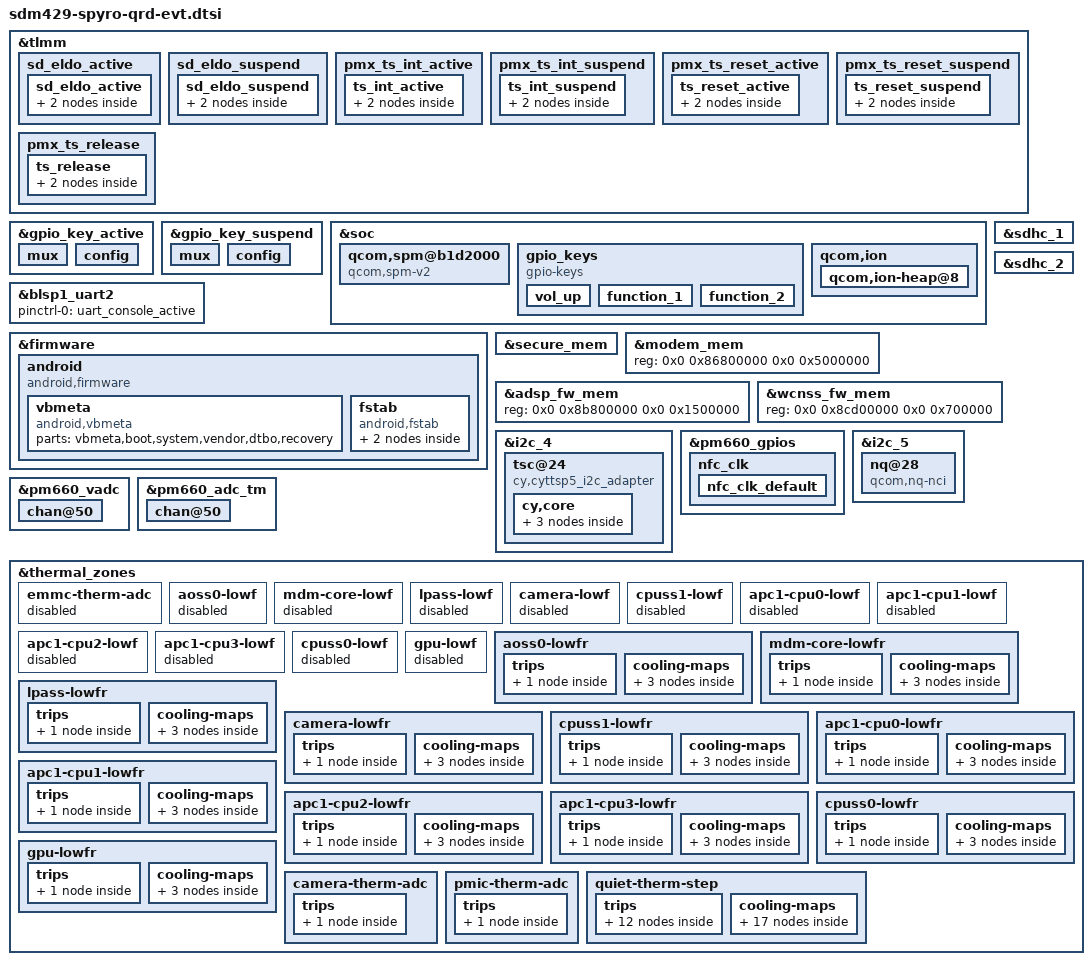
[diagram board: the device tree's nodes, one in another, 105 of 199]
/*
 * Copyright (c) 2019, The Linux Foundation. All rights reserved.
 *
 * This program is free software; you can redistribute it and/or modify
 * it under the terms of the GNU General Public License version 2 and
 * only version 2 as published by the Free Software Foundation.
 *
 * This program is distributed in the hope that it will be useful,
 * but WITHOUT ANY WARRANTY; without even the implied warranty of
 * MERCHANTABILITY or FITNESS FOR A PARTICULAR PURPOSE.  See the
 * GNU General Public License for more details.
 */

#include "sdm429-spyro-qrd-mdss-panels.dtsi"
#include "sdm429-spyro-qrd-evt-camera.dtsi"
#include "sdm429-spyro-qrd-evt-audio.dtsi"
#include <dt-bindings/thermal/thermal.h>

&tlmm {
	sd_eldo_active {
		sd_eldo_active: sd_eldo_active {
			mux {
				pins = "gpio91";
				function = "gpio";
			};

			config {
				pins = "gpio91";
				drive-strength = <2>;
				bias-pull-up;
			};
		};
	};

	sd_eldo_suspend {
		sd_eldo_suspend: sd_eldo_suspend {
			mux {
				pins = "gpio91";
				function = "gpio";
			};

			config {
				pins = "gpio91";
				drive-strength = <2>;
				bias-disable;
			};
		};
	};
};

&gpio_key_active {
	mux {
		pins = "gpio127", "gpio128", "gpio35", "gpio126";
		function = "gpio";
	};

	config {
		pins = "gpio127", "gpio128", "gpio35", "gpio126";
		drive-strength = <2>;
		bias-pull-up;
	};
};

&gpio_key_suspend {
	mux {
		pins = "gpio127", "gpio128", "gpio35", "gpio126";
		function = "gpio";
	};

	config {
		pins = "gpio127", "gpio128", "gpio35", "gpio126";
		drive-strength = <2>;
		bias-pull-up;
	};
};

&soc {
	/delete-node/ qcom,spm@b1d2000;
	qcom,spm@b1d2000 {
		compatible = "qcom,spm-v2";
		#address-cells = <1>;
		#size-cells = <1>;
		reg = <0xb1d2000 0x1000>;
		qcom,name = "system-cci";
		qcom,saw2-ver-reg = <0xfd0>;
		qcom,saw2-cfg = <0x14>;
		qcom,saw2-spm-dly= <0x3C102800>;
		qcom,saw2-spm-ctl = <0xe>;
		qcom,cpu-vctl-list = <&CPU0 &CPU1 &CPU2 &CPU3>;
		qcom,vctl-timeout-us = <500>;
		qcom,vctl-port = <0x0>;
		qcom,vctl-port-ub = <0x1>;
		qcom,pfm-port = <0x2>;
	};

	gpio_keys: gpio_keys {
		compatible = "gpio-keys";
		label = "gpio-keys";
		pinctrl-names = "default";
		pinctrl-0 = <&gpio_key_active>;
		pinctrl-1 = <&gpio_key_suspend>;

		vol_up: vol_up {
			label = "volume_up";
			gpios = <&tlmm 35 0x1>;
			linux,input-type = <1>;
			linux,code = <115>;
			debounce-interval = <15>;
			linux,can-disable;
			gpio-key,wakeup;
		};

		function_1: function_1 {
			label = "function_1";
			gpios = <&tlmm 127 0x1>;
			linux,input-type = <1>;
			linux,code = <116>;
			debounce-interval = <15>;
			linux,can-disable;
			gpio-key,wakeup;
		};

		function_2: function_2 {
			label = "function_2";
			gpios = <&tlmm 126 0x1>;
			linux,input-type = <1>;
			linux,code = <117>;
			debounce-interval = <15>;
			linux,can-disable;
			gpio-key,wakeup;
		};
	};
};

&blsp1_uart2 {
	status = "ok";
	pinctrl-names = "default";
	pinctrl-0 = <&uart_console_active>;
};

&sdhc_1 {
	/* device core power supply */
	vdd-supply = <&L19A>;
	qcom,vdd-voltage-level = <2900000 3200000>;
	qcom,vdd-current-level = <200 570000>;

	/* device communication power supply */
	vdd-io-supply = <&L13A>;
	qcom,vdd-io-always-on;
	qcom,vdd-io-lpm-sup;
	qcom,vdd-io-voltage-level = <1800000 1800000>;
	qcom,vdd-io-current-level = <0 60000>;

	pinctrl-names = "active", "sleep";
	pinctrl-0 = <&sdc1_clk_on &sdc1_cmd_on &sdc1_data_on &sdc1_rclk_on>;
	pinctrl-1 = <&sdc1_clk_off &sdc1_cmd_off &sdc1_data_off &sdc1_rclk_off>;

	qcom,clk-rates = <400000 20000000 25000000 50000000 100000000 192000000
								384000000>;
	qcom,nonremovable;
	qcom,bus-speed-mode = "HS400_1p8v", "HS200_1p8v", "DDR_1p8v";

	status = "ok";
};

&sdhc_2 {
	/* device core power supply for sd card*/
	vdd-supply = <&vreg_sd_vdd>;
	qcom,vdd-voltage-level = <2950000 2950000>;
	qcom,vdd-current-level = <15000 800000>;

	/* device communication power supply for msm_io*/
	vdd-io-supply = <&vreg_sd_pad>;
	qcom,vdd-io-voltage-level = <1800000 2950000>;
	qcom,vdd-io-current-level = <200 22000>;

	pinctrl-names = "active", "sleep";
	pinctrl-0 = <&sdc2_clk_on &sdc2_cmd_on &sdc2_data_on &sdc2_cd_on
							&sd_eldo_active>;
	pinctrl-1 = <&sdc2_clk_off &sdc2_cmd_off &sdc2_data_off &sdc2_cd_off
							&sd_eldo_suspend>;

	cd-gpios = <&tlmm 67 0x0>;

	qcom,clk-rates = <400000 20000000 25000000 50000000 100000000
								200000000>;

	qcom,bus-speed-mode = "SDR12", "SDR25", "SDR50", "DDR50", "SDR104";

	status = "ok";
};

&firmware {
	android {
		compatible = "android,firmware";
		vbmeta {
			compatible = "android,vbmeta";
			parts = "vbmeta,boot,system,vendor,dtbo,recovery";
		};
		fstab {
			compatible = "android,fstab";
			vendor {
				compatible = "android,vendor";
				dev =
		"/dev/block/platform/soc/7824900.sdhci/by-name/vendor";
				type = "ext4";
				mnt_flags = "ro,barrier=1,discard";
				fsmgr_flags = "wait";
				status = "ok";
			};
			system {
				compatible = "android,system";
				dev =
		"/dev/block/platform/soc/7824900.sdhci/by-name/system";
				type = "ext4";
				mnt_flags = "ro,barrier=1,discard";
				fsmgr_flags = "wait";
				status = "ok";
			};
		};
	};
};

&soc {
	qcom,ion {
		qcom,ion-heap@8 { /* CP_MM HEAP */
			reg = <8>;
			memory-region = <&secure_mem>;
			qcom,ion-heap-type = "SECURE_DMA";
		};
	};
};

&secure_mem {
	alignment = <0 0x400000>;
	size = <0 0x800000>;
	status = "okay";
};

&modem_mem {
	reg = <0x0 0x86800000 0x0 0x5000000>;
};

&adsp_fw_mem {
	reg = <0x0 0x8b800000 0x0 0x1500000>;
};

&wcnss_fw_mem {
	reg = <0x0 0x8cd00000 0x0 0x700000>;
};

&i2c_4 {
	status = "ok";

	tsc@24 {
		compatible = "cy,cyttsp5_i2c_adapter";
		reg = <0x24>;

		interrupt-parent = <&tlmm>;
		interrupts = <65 0x2008>;
		cy,adapter_id = "cyttsp5_i2c_adapter";
		vcc_i2c-supply = <&L13A>;
		vdd-supply = <&L15A>;
		pinctrl-names = "pmx_ts_active", "pmx_ts_suspend",
				"pmx_ts_release";
		pinctrl-0 = <&ts_int_active &ts_reset_active>;
		pinctrl-1 = <&ts_int_suspend &ts_reset_suspend>;
		pinctrl-2 = <&ts_release>;

		cy,core {
			cy,name = "cyttsp5_core";
			cy,irq_gpio = <65>;
			cy,rst_gpio = <64>;
			cy,hid_desc_register = <1>;
			cy,flags = <4>;
			cy,easy_wakeup_gesture = <1>;
			cy,btn_keys = <172 139 158 217 114 115 212 116>;
			cy,btn_keys-tag = <0>;

			cy,mt {
				cy,name = "cyttsp5_mt";

				cy,inp_dev_name = "cyttsp5_mt";
				cy,flags = <0x28>;
				cy,abs =
					<0x35 0 320 0 0
					 0x36 0 360 0 0
					 0x3a 0 255 0 0
					 0xffff 0 255 0 0
					 0x39 0 15 0 0
					 0x30 0 255 0 0
					 0x31 0 255 0 0
					 0x34 0xffffff81 127 0 0
					 0x37 0 1 0 0
					 0x3b 0 255 0 0>;

				cy,vkeys_x = <320>;
				cy,vkeys_y = <360>;

				cy,virtual_keys =
					<158 1360 90 160 180
					 139 1360 270 160 180
					 172 1360 450 160 180
					 217 1360 630 160 180>;
			};

			cy,btn {
				cy,name = "cyttsp5_btn";

				cy,inp_dev_name = "cyttsp5_btn";
			};

			cy,proximity {
				cy,name = "cyttsp5_proximity";

				cy,inp_dev_name = "cyttsp5_proximity";
				cy,abs = <0x19 0 1 0 0>;
			};
		};
	};

};

&pm660_gpios {
	nfc_clk {
		nfc_clk_default: nfc_clk_default {
			pins = "gpio4";
			function = "normal";
			input-enable;
			power-source = <1>;
		};
	};
};

&i2c_5 { /* BLSP2 QUP1 (NFC) */
	#address-cells = <1>;
	#size-cells = <0>;

	status = "ok";
	nq@28 {
		compatible = "qcom,nq-nci";
		reg = <0x28>;
		qcom,nq-irq = <&tlmm 17 0x00>;
		qcom,nq-ven = <&tlmm 16 0x00>;
		qcom,nq-firm = <&tlmm 130 0x00>;
		qcom,nq-clkreq = <&pm660_gpios 4 0x00>;
		qcom,nq-esepwr = <&tlmm 93 0x00>;
		interrupt-parent = <&tlmm>;
		qcom,clk-src = "BBCLK2";
		interrupts = <17 0>;
		interrupt-names = "nfc_irq";
		pinctrl-names = "nfc_active", "nfc_suspend";
		pinctrl-0 = <&nfc_int_active &nfc_disable_active
						&nfc_clk_default>;
		pinctrl-1 = <&nfc_int_suspend &nfc_disable_suspend>;
		clocks = <&clock_gcc clk_bb_clk2_pin>;
		clock-names = "ref_clk";
	};
};

&tlmm {
	pmx_ts_int_active {
		ts_int_active: ts_int_active {
			mux {
				pins = "gpio65";
				function = "gpio";
			};

			config {
				pins = "gpio65";
				drive-strength = <8>;
				bias-pull-up;
			};
		};
	};

	pmx_ts_int_suspend {
		ts_int_suspend: ts_int_suspend {
			mux {
				pins = "gpio65";
				function = "gpio";
			};

			config {
				pins = "gpio65";
				drive-strength = <2>;
				bias-pull-down;
			};
		};
	};

	pmx_ts_reset_active {
		ts_reset_active: ts_reset_active {
			mux {
				pins = "gpio64";
				function = "gpio";
			};

			config {
				pins = "gpio64";
				drive-strength = <8>;
				bias-pull-up;
			};
		};
	};

	pmx_ts_reset_suspend {
		ts_reset_suspend: ts_reset_suspend {
			mux {
				pins = "gpio64";
				function = "gpio";
			};

			config {
				pins = "gpio64";
				drive-strength = <2>;
				bias-pull-down;
			};
		};
	};

	pmx_ts_release {
		ts_release: ts_release {
			mux {
				pins = "gpio65", "gpio64";
				function = "gpio";
			};

			config {
				pins = "gpio65", "gpio64";
				drive-strength = <2>;
				bias-pull-down;
			};
		};
	};

};

&pm660_vadc {
	chan@50 {
		label = "pmic_therm";
		reg = <0x50>;
		qcom,decimation = <2>;
		qcom,pre-div-channel-scaling = <0>;
		qcom,calibration-type = "ratiometric";
		qcom,scale-function = <2>;
		qcom,hw-settle-time = <2>;
		qcom,fast-avg-setup = <0>;
	};
};

&pm660_adc_tm {
	chan@50 {
		label = "pmic_therm";
		reg = <0x50>;
		qcom,pre-div-channel-scaling = <0>;
		qcom,calibration-type = "ratiometric";
		qcom,scale-function = <2>;
		qcom,hw-settle-time = <2>;
		qcom,btm-channel-number = <0x48>;
		qcom,thermal-node;
	};
};

&thermal_zones {

	emmc-therm-adc {
		status = "disabled";
	};

	aoss0-lowf {
		status = "disabled";
	};

	mdm-core-lowf {
		status = "disabled";
	};

	lpass-lowf {
		status = "disabled";
	};

	camera-lowf {
		status = "disabled";
	};

	cpuss1-lowf {
		status = "disabled";
	};

	apc1-cpu0-lowf {
		status = "disabled";
	};

	apc1-cpu1-lowf {
		status = "disabled";
	};

	apc1-cpu2-lowf {
		status = "disabled";
	};

	apc1-cpu3-lowf {
		status = "disabled";
	};

	cpuss0-lowf {
		status = "disabled";
	};

	gpu-lowf {
		status = "disabled";
	};

	aoss0-lowfr {
		polling-delay-passive = <0>;
		polling-delay = <0>;
		thermal-governor = "low_limits_floor";
		thermal-sensors = <&tsens0 0>;
		tracks-low;

		trips {
			aoss0_trip: aoss-trip {
				temperature = <5000>;
				hysteresis = <5000>;
				type = "passive";
			};
		};

		cooling-maps {
			cpu0_vdd_cdev {
				trip = <&aoss0_trip>;
				cooling-device = <&CPU0 (THERMAL_MAX_LIMIT-2)
						(THERMAL_MAX_LIMIT-2)>;
			};

			cx_vdd_cdev {
				trip = <&aoss0_trip>;
				cooling-device = <&pm660_cx_cdev 0 0>;
			};

			modem_vdd_cdev {
				trip = <&aoss0_trip>;
				cooling-device = <&modem_vdd 0 0>;
			};
		};
	};

	mdm-core-lowfr {
		polling-delay-passive = <0>;
		polling-delay = <0>;
		thermal-governor = "low_limits_floor";
		thermal-sensors = <&tsens0 1>;
		tracks-low;

		trips {
			mdm_core_trip: mdm-core-trip {
				temperature = <5000>;
				hysteresis = <5000>;
				type = "passive";
			};
		};

		cooling-maps {
			cpu0_vdd_cdev {
				trip = <&mdm_core_trip>;
				cooling-device = <&CPU0 (THERMAL_MAX_LIMIT-2)
						(THERMAL_MAX_LIMIT-2)>;
			};

			cx_vdd_cdev {
				trip = <&mdm_core_trip>;
				cooling-device = <&pm660_cx_cdev 0 0>;
			};

			modem_vdd_cdev {
				trip = <&mdm_core_trip>;
				cooling-device = <&modem_vdd 0 0>;
			};
		};
	};

	lpass-lowfr {
		polling-delay-passive = <0>;
		polling-delay = <0>;
		thermal-governor = "low_limits_floor";
		thermal-sensors = <&tsens0 2>;
		tracks-low;

		trips {
			qdsp_trip: qdsp-trip {
				temperature = <5000>;
				hysteresis = <5000>;
				type = "passive";
			};
		};

		cooling-maps {
			cpu0_vdd_cdev {
				trip = <&qdsp_trip>;
				cooling-device = <&CPU0 (THERMAL_MAX_LIMIT-2)
						(THERMAL_MAX_LIMIT-2)>;
			};

			cx_vdd_cdev {
				trip = <&qdsp_trip>;
				cooling-device = <&pm660_cx_cdev 0 0>;
			};

			modem_vdd_cdev {
				trip = <&qdsp_trip>;
				cooling-device = <&modem_vdd 0 0>;
			};
		};
	};

	camera-lowfr {
		polling-delay-passive = <0>;
		polling-delay = <0>;
		thermal-governor = "low_limits_floor";
		thermal-sensors = <&tsens0 3>;
		tracks-low;

		trips {
			camera_trip: camera-trip {
				temperature = <5000>;
				hysteresis = <5000>;
				type = "passive";
			};
		};

		cooling-maps {
			cpu0_vdd_cdev {
				trip = <&camera_trip>;
				cooling-device = <&CPU0 (THERMAL_MAX_LIMIT-2)
						(THERMAL_MAX_LIMIT-2)>;
			};

			cx_vdd_cdev {
				trip = <&camera_trip>;
				cooling-device = <&pm660_cx_cdev 0 0>;
			};

			modem_vdd_cdev {
				trip = <&camera_trip>;
				cooling-device = <&modem_vdd 0 0>;
			};
		};
	};

	cpuss1-lowfr {
		polling-delay-passive = <0>;
		polling-delay = <0>;
		thermal-governor = "low_limits_floor";
		thermal-sensors = <&tsens0 4>;
		tracks-low;

		trips {
			cpuss1_trip: cpuss1-trip {
				temperature = <5000>;
				hysteresis = <5000>;
				type = "passive";
			};
		};

		cooling-maps {
			cpu0_vdd_cdev {
				trip = <&cpuss1_trip>;
				cooling-device = <&CPU0 (THERMAL_MAX_LIMIT-2)
					(THERMAL_MAX_LIMIT-2)>;
			};

			cx_vdd_cdev {
				trip = <&cpuss1_trip>;
				cooling-device = <&pm660_cx_cdev 0 0>;
			};

			modem_vdd_cdev {
				trip = <&cpuss1_trip>;
				cooling-device = <&modem_vdd 0 0>;
			};
		};
	};

	apc1-cpu0-lowfr {
		polling-delay-passive = <0>;
		polling-delay = <0>;
		thermal-governor = "low_limits_floor";
		thermal-sensors = <&tsens0 5>;
		tracks-low;

		trips {
			cpu0_trip: apc1-cpu0-trip {
				temperature = <5000>;
				hysteresis = <5000>;
				type = "passive";
			};
		};

		cooling-maps {
			cpu0_vdd_cdev {
				trip = <&cpu0_trip>;
				cooling-device = <&CPU0 (THERMAL_MAX_LIMIT-2)
						(THERMAL_MAX_LIMIT-2)>;
			};

			cx_vdd_cdev {
				trip = <&cpu0_trip>;
				cooling-device = <&pm660_cx_cdev 0 0>;
			};

			modem_vdd_cdev {
				trip = <&cpu0_trip>;
				cooling-device = <&modem_vdd 0 0>;
			};
		};
	};

	apc1-cpu1-lowfr {
		polling-delay-passive = <0>;
		polling-delay = <0>;
		thermal-governor = "low_limits_floor";
		thermal-sensors = <&tsens0 6>;
		tracks-low;

		trips {
			cpu1_trip: apc1-cpu1-trip {
				temperature = <5000>;
				hysteresis = <5000>;
				type = "passive";
			};
		};

		cooling-maps {
			cpu0_vdd_cdev {
				trip = <&cpu1_trip>;
				cooling-device = <&CPU0 (THERMAL_MAX_LIMIT-2)
						(THERMAL_MAX_LIMIT-2)>;
			};

			cx_vdd_cdev {
				trip = <&cpu1_trip>;
				cooling-device = <&pm660_cx_cdev 0 0>;
			};

			modem_vdd_cdev {
				trip = <&cpu1_trip>;
				cooling-device = <&modem_vdd 0 0>;
			};
		};
	};

	apc1-cpu2-lowfr {
		polling-delay-passive = <0>;
		polling-delay = <0>;
		thermal-governor = "low_limits_floor";
		thermal-sensors = <&tsens0 7>;
		tracks-low;

		trips {
			cpu2_trip: apc1-cpu2-trip {
				temperature = <5000>;
				hysteresis = <5000>;
				type = "passive";
			};
		};

		cooling-maps {
			cpu0_vdd_cdev {
				trip = <&cpu2_trip>;
				cooling-device = <&CPU0 (THERMAL_MAX_LIMIT-2)
						(THERMAL_MAX_LIMIT-2)>;
			};

			cx_vdd_cdev {
				trip = <&cpu2_trip>;
				cooling-device = <&pm660_cx_cdev 0 0>;
			};

			modem_vdd_cdev {
				trip = <&cpu2_trip>;
				cooling-device = <&modem_vdd 0 0>;
			};
		};
	};

	apc1-cpu3-lowfr {
		polling-delay-passive = <0>;
		polling-delay = <0>;
		thermal-governor = "low_limits_floor";
		thermal-sensors = <&tsens0 8>;
		tracks-low;

		trips {
			cpu3_trip: apc1-cpu3-trip {
				temperature = <5000>;
				hysteresis = <5000>;
				type = "passive";
			};
		};

		cooling-maps {
			cpu0_vdd_cdev {
				trip = <&cpu3_trip>;
				cooling-device = <&CPU0 (THERMAL_MAX_LIMIT-2)
						(THERMAL_MAX_LIMIT-2)>;
			};

			cx_vdd_cdev {
				trip = <&cpu3_trip>;
				cooling-device = <&pm660_cx_cdev 0 0>;
			};

			modem_vdd_cdev {
				trip = <&cpu3_trip>;
				cooling-device = <&modem_vdd 0 0>;
			};
		};
	};

	cpuss0-lowfr {
		polling-delay-passive = <0>;
		polling-delay = <0>;
		thermal-governor = "low_limits_floor";
		thermal-sensors = <&tsens0 9>;
		tracks-low;

		trips {
			cpuss0_lowf_trip: cpuss0-lowf-trip {
				temperature = <5000>;
				hysteresis = <5000>;
				type = "passive";
			};
		};

		cooling-maps {
			cpu0_vdd_cdev {
				trip = <&cpuss0_lowf_trip>;
				cooling-device = <&CPU0 (THERMAL_MAX_LIMIT-2)
						(THERMAL_MAX_LIMIT-2)>;
			};

			cx_vdd_cdev {
				trip = <&cpuss0_lowf_trip>;
				cooling-device = <&pm660_cx_cdev 0 0>;
			};

			modem_vdd_cdev {
				trip = <&cpuss0_lowf_trip>;
				cooling-device = <&modem_vdd 0 0>;
			};
		};
	};

	gpu-lowfr {
		polling-delay-passive = <0>;
		polling-delay = <0>;
		thermal-governor = "low_limits_floor";
		thermal-sensors = <&tsens0 10>;
		tracks-low;

		trips {
			gpu_lowf_trip: gpu-lowf-trip {
				temperature = <5000>;
				hysteresis = <5000>;
				type = "passive";
			};
		};

		cooling-maps {
			cpu0_vdd_cdev {
				trip = <&gpu_lowf_trip>;
				cooling-device = <&CPU0 (THERMAL_MAX_LIMIT-2)
						(THERMAL_MAX_LIMIT-2)>;
			};

			cx_vdd_cdev {
				trip = <&gpu_lowf_trip>;
				cooling-device = <&pm660_cx_cdev 0 0>;
			};

			modem_vdd_cdev {
				trip = <&gpu_lowf_trip>;
				cooling-device = <&modem_vdd 0 0>;
			};
		};
	};

	camera-therm-adc {
		polling-delay-passive = <0>;
		polling-delay = <0>;
		thermal-sensors = <&pm660_adc_tm 0x4e>;
		wake-capable-sensor;
		thermal-governor = "user_space";

		trips {
			active-config0 {
				temperature = <65000>;
				hysteresis = <1000>;
				type = "passive";
			};
		};
	};

	pmic-therm-adc {
		polling-delay-passive = <0>;
		polling-delay = <0>;
		thermal-sensors = <&pm660_adc_tm 0x50>;
		wake-capable-sensor;
		thermal-governor = "user_space";

		trips {
			active-config0 {
				temperature = <65000>;
				hysteresis = <1000>;
				type = "passive";
			};
		};
	};

	quiet-therm-step {
		polling-delay-passive = <1000>;
		polling-delay = <0>;
		thermal-sensors = <&pm660_adc_tm 0x51>;
		thermal-governor = "step_wise";

		trips {
			quiet_batt_439_trip1: quiet-batt-trip1 {
				temperature = <38000>;
				hysteresis = <2000>;
				type = "passive";
			};

			quiet_batt_439_trip2: quiet-batt-trip2 {
				temperature = <40000>;
				hysteresis = <2000>;
				type = "passive";
			};

			quiet_batt_439_trip3: quiet-batt-trip3 {
				temperature = <42000>;
				hysteresis = <2000>;
				type = "passive";
			};

			quiet_batt_439_trip4: quiet-batt-trip4 {
				temperature = <44000>;
				hysteresis = <2000>;
				type = "passive";
			};

			quiet_modem_439_trip1: quiet-modem-trip0 {
				temperature = <44000>;
				hysteresis = <4000>;
				type = "passive";
			};

			quiet_modem_439_trip2: quiet-modem-trip1 {
				temperature = <46000>;
				hysteresis = <4000>;
				type = "passive";
			};

			quiet_batt_439_trip5: quiet-batt-trip5 {
				temperature = <46000>;
				hysteresis = <2000>;
				type = "passive";
			};

			quiet_439_batt_trip6_mdm_trip3: quiet-bt-trp6-mdm-trp3 {
				temperature = <48000>;
				hysteresis = <2000>;
				type = "passive";
			};

			quiet_cpus_439_trip: quiet-cpus-trip {
				temperature = <48000>;
				hysteresis = <0>;
				type = "passive";
			};

			quiet_gpu_439_trip: quiet-gpu-trip {
				temperature = <50000>;
				hysteresis = <0>;
				type = "passive";
			};

			quiet_batt_439_trip7: quiet-batt-trip7 {
				temperature = <50000>;
				hysteresis = <2000>;
				type = "passive";
			};

			quiet_modem_439_trip4: quiet-modem-trip3 {
				temperature = <55000>;
				hysteresis = <5000>;
				type = "passive";
			};
		};

		cooling-maps {
			skin_cpu0 {
				trip = <&quiet_cpus_439_trip>;
				/* throttle from fmax to 1497600KHz */
				cooling-device = <&CPU0 THERMAL_NO_LIMIT
						(THERMAL_MAX_LIMIT-3)>;
			};

			skin_cpu1 {
				trip = <&quiet_cpus_439_trip>;
				cooling-device = <&CPU1 THERMAL_NO_LIMIT
						(THERMAL_MAX_LIMIT-3)>;
			};

			skin_cpu2 {
				trip = <&quiet_cpus_439_trip>;
				cooling-device = <&CPU2 THERMAL_NO_LIMIT
						(THERMAL_MAX_LIMIT-3)>;
			};

			skin_cpu3 {
				trip = <&quiet_cpus_439_trip>;
				cooling-device = <&CPU3 THERMAL_NO_LIMIT
						(THERMAL_MAX_LIMIT-3)>;
			};

			skin_gpu {
				trip = <&quiet_gpu_439_trip>;
				/* throttle from fmax to 510000000Hz */
				cooling-device = <&msm_gpu THERMAL_NO_LIMIT
						(THERMAL_MAX_LIMIT-2)>;
			};

			modem_proc_lvl1 {
				trip = <&quiet_modem_439_trip1>;
				cooling-device = <&modem_proc 1 1>;
			};

			modem_proc_lvl2 {
				trip = <&quiet_modem_439_trip4>;
				cooling-device = <&modem_proc 3 3>;
			};

			modem_lvl1 {
				trip = <&quiet_modem_439_trip2>;
				cooling-device = <&modem_pa 1 1>;
			};

			modem_lvl2 {
				trip = <&quiet_439_batt_trip6_mdm_trip3>;
				cooling-device = <&modem_pa 2 2>;
			};

			modem_lvl3 {
				trip = <&quiet_modem_439_trip4>;
				cooling-device = <&modem_pa 3 3>;
			};

			battery_lvl1 {
				trip = <&quiet_batt_439_trip1>;
				cooling-device = <&pm660_charger 1 1>;
			};

			battery_lvl2 {
				trip = <&quiet_batt_439_trip2>;
				cooling-device = <&pm660_charger 2 2>;
			};

			battery_lvl3 {
				trip = <&quiet_batt_439_trip3>;
				cooling-device = <&pm660_charger 3 3>;
			};

			battery_lvl4 {
				trip = <&quiet_batt_439_trip4>;
				cooling-device = <&pm660_charger 4 4>;
			};

			battery_lvl5 {
				trip = <&quiet_batt_439_trip5>;
				cooling-device = <&pm660_charger 5 5>;
			};

			battery_lvl6 {
				trip = <&quiet_439_batt_trip6_mdm_trip3>;
				cooling-device = <&pm660_charger 6 6>;
			};

			battery_lvl7 {
				trip = <&quiet_batt_439_trip7>;
				cooling-device = <&pm660_charger 7 7>;
			};
		};
	};
};
